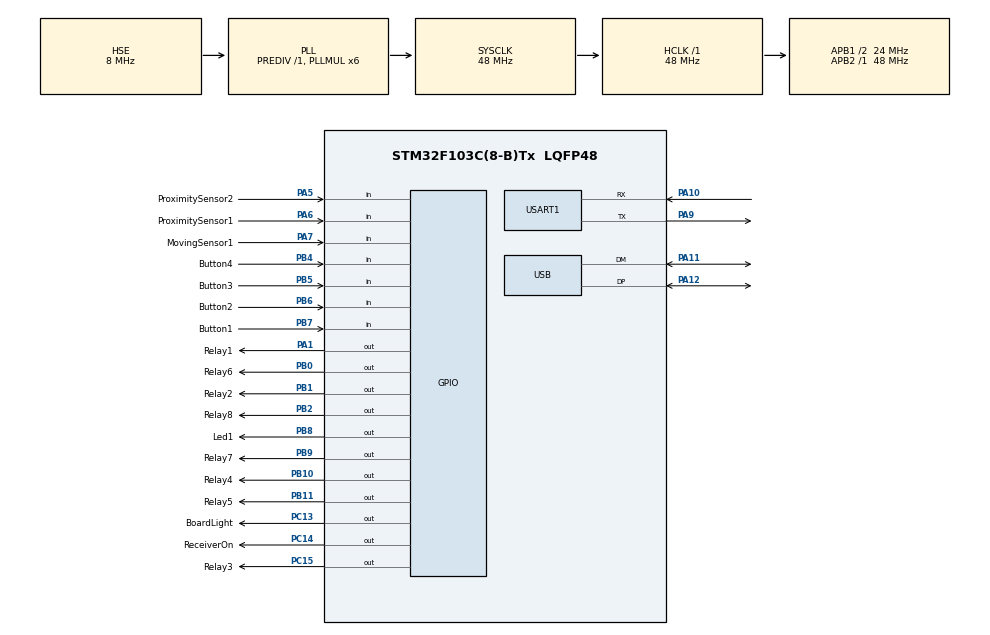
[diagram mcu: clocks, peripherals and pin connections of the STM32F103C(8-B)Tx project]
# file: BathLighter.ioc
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Dma.Request0=USART1_RX
Dma.Request1=USART1_TX
Dma.USART1_RX.0.Direction=DMA_PERIPH_TO_MEMORY
Dma.USART1_RX.0.Instance=DMA1_Channel5
Dma.USART1_RX.0.MemDataAlignment=DMA_MDATAALIGN_BYTE
Dma.USART1_RX.0.MemInc=DMA_MINC_ENABLE
Dma.USART1_RX.0.Mode=DMA_NORMAL
Dma.USART1_RX.0.PeriphDataAlignment=DMA_PDATAALIGN_BYTE
Dma.USART1_RX.0.PeriphInc=DMA_PINC_DISABLE
Dma.USART1_RX.0.Priority=DMA_PRIORITY_LOW
Dma.USART1_TX.1.Direction=DMA_MEMORY_TO_PERIPH
Dma.USART1_TX.1.Instance=DMA1_Channel4
Dma.USART1_TX.1.MemDataAlignment=DMA_MDATAALIGN_BYTE
Dma.USART1_TX.1.MemInc=DMA_MINC_ENABLE
Dma.USART1_TX.1.Mode=DMA_NORMAL
Dma.USART1_TX.1.PeriphDataAlignment=DMA_PDATAALIGN_BYTE
Dma.USART1_TX.1.PeriphInc=DMA_PINC_DISABLE
Dma.USART1_TX.1.Priority=DMA_PRIORITY_LOW
FREERTOS.Tasks01=NetTask,0,128,StartNetTask,Default,NULL,Dynamic,NULL,NULL;ReadSensors,0,128,StartReadSensorsTask,Default,NULL,Dynamic,NULL,NULL;Drive,0,128,StartDriveTask,Default,NULL,Dynamic,NULL,NULL
Mcu.Family=STM32F1
Mcu.Name=STM32F103C(8-B)Tx
Mcu.Package=LQFP48
Mcu.UserConstants=Timer2TicksMax,500
NVIC.DMA1_Channel4_IRQn=true\:5\:0\:false\:false\:true\:true\:false\:true
NVIC.DMA1_Channel5_IRQn=true\:5\:0\:false\:false\:true\:true\:false\:true
NVIC.PriorityGroup=NVIC_PRIORITYGROUP_4
NVIC.TIM1_UP_IRQn=true\:0\:0\:false\:false\:true\:false\:false\:true
NVIC.TIM2_IRQn=true\:5\:0\:false\:false\:true\:true\:true\:true
NVIC.TimeBase=TIM1_UP_IRQn
NVIC.TimeBaseIP=TIM1
NVIC.USART1_IRQn=true\:5\:0\:false\:false\:true\:true\:true\:true
NVIC.USB_HP_CAN1_TX_IRQn=true\:5\:0\:false\:false\:true\:true\:true\:true
NVIC.USB_LP_CAN1_RX0_IRQn=true\:5\:0\:false\:false\:true\:true\:false\:true
PA1.GPIO_Label=Relay1
PA1.Signal=GPIO_Output
PA10.Mode=Asynchronous
PA10.Signal=USART1_RX
PA11.Mode=Device
PA11.Signal=USB_DM
PA12.Mode=Device
PA12.Signal=USB_DP
PA13.Mode=Serial_Wire
PA13.Signal=SYS_JTMS-SWDIO
PA14.Mode=Serial_Wire
PA14.Signal=SYS_JTCK-SWCLK
PA5.GPIO_Label=ProximitySensor2
PA5.Signal=GPIO_Input
PA6.GPIO_Label=ProximitySensor1
PA6.Signal=GPIO_Input
PA7.GPIO_Label=MovingSensor1
PA7.Signal=GPIO_Input
PA9.Mode=Asynchronous
PA9.Signal=USART1_TX
PB0.GPIO_Label=Relay6
PB0.Signal=GPIO_Output
PB1.GPIO_Label=Relay2
PB1.Signal=GPIO_Output
PB10.GPIO_Label=Relay4
PB10.Signal=GPIO_Output
PB11.GPIO_Label=Relay5
PB11.Signal=GPIO_Output
PB2.GPIO_Label=Relay8
PB2.Signal=GPIO_Output
PB4.GPIO_Label=Button4
PB4.GPIO_PuPd=GPIO_NOPULL
PB4.Signal=GPIO_Input
PB5.GPIO_Label=Button3
PB5.GPIO_PuPd=GPIO_NOPULL
PB5.Signal=GPIO_Input
PB6.GPIO_Label=Button2
PB6.GPIO_PuPd=GPIO_NOPULL
PB6.Signal=GPIO_Input
PB7.GPIO_Label=Button1
PB7.GPIO_PuPd=GPIO_NOPULL
PB7.Signal=GPIO_Input
PB8.GPIO_Label=Led1
PB8.Signal=GPIO_Output
PB9.GPIO_Label=Relay7
PB9.Signal=GPIO_Output
PC13-TAMPER-RTC.GPIO_Label=BoardLight
PC13-TAMPER-RTC.Signal=GPIO_Output
PC14-OSC32_IN.GPIO_Label=ReceiverOn
PC14-OSC32_IN.Signal=GPIO_Output
PC15-OSC32_OUT.GPIO_Label=Relay3
PC15-OSC32_OUT.Signal=GPIO_Output
PD0-OSC_IN.Mode=HSE-External-Oscillator
PD0-OSC_IN.Signal=RCC_OSC_IN
PD1-OSC_OUT.Mode=HSE-External-Oscillator
PD1-OSC_OUT.Signal=RCC_OSC_OUT
ProjectManager.HeapSize=0x200
ProjectManager.StackSize=0x400
ProjectManager.TargetToolchain=EWARM V7
RCC.AHBFreq_Value=48000000
RCC.APB1CLKDivider=RCC_HCLK_DIV2
RCC.APB1Freq_Value=24000000
RCC.APB1TimFreq_Value=48000000
RCC.APB2Freq_Value=48000000
RCC.APB2TimFreq_Value=48000000
RCC.HCLKFreq_Value=48000000
RCC.PLLMUL=RCC_PLL_MUL6
RCC.SYSCLKFreq_VALUE=48000000
RCC.SYSCLKSource=RCC_SYSCLKSOURCE_PLLCLK
RCC.USBFreq_Value=48000000
TIM2.Period=9
TIM2.Prescaler=47999
USART1.VirtualMode=VM_ASYNC
USB_DEVICE.CLASS_NAME_FS=CUSTOM_HID
USB_DEVICE.USBD_CUSTOMHID_OUTREPORT_BUF_SIZE=16
USB_DEVICE.USBD_CUSTOM_HID_REPORT_DESC_SIZE=84
USB_DEVICE.VID=1164
USB_DEVICE.VirtualMode=CustomHid
USB_DEVICE.VirtualModeFS=Custom_Hid_FS
VP_FREERTOS_VS_CMSIS_V1.Mode=CMSIS_V1
VP_RTC_VS_RTC_Activate.Mode=RTC_Enabled
VP_RTC_VS_RTC_Calendar.Mode=RTC_Calendar
VP_SYS_VS_tim1.Mode=TIM1
VP_TIM2_VS_ClockSourceINT.Mode=Internal
VP_USB_DEVICE_VS_USB_DEVICE_CUSTOM_HID_FS.Mode=CUSTOM_HID_FS
board=NetMaster

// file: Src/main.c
/* USER CODE BEGIN Header */
/**
  ******************************************************************************
  * @file           : main.c
  * @brief          : Main program body
  ******************************************************************************
  * @attention
  *
  * <h2><center>&copy; Copyright (c) 2019 STMicroelectronics.
  * All rights reserved.</center></h2>
  *
  * This software component is licensed by ST under Ultimate Liberty license
  * SLA0044, the "License"; You may not use this file except in compliance with
  * the License. You may obtain a copy of the License at:
  *                             www.st.com/SLA0044
  *
  ******************************************************************************
  */
/* USER CODE END Header */

#include "main.h"
#include "cmsis_os.h"
#include "usb_device.h"

/* USER CODE BEGIN Includes */
#include "TasksForAll.h"
/* USER CODE END Includes */

RTC_HandleTypeDef hrtc;

TIM_HandleTypeDef htim2;

UART_HandleTypeDef huart1;
DMA_HandleTypeDef hdma_usart1_rx;
DMA_HandleTypeDef hdma_usart1_tx;

osThreadId NetTaskHandle;
osThreadId ReadSensorsHandle;
osThreadId DriveHandle;

void SystemClock_Config(void);
static void MX_GPIO_Init(void);
static void MX_DMA_Init(void);
static void MX_TIM2_Init(void);
static void MX_USART1_UART_Init(void);
static void MX_RTC_Init(void);
void StartNetTask(void const * argument);
void StartReadSensorsTask(void const * argument);
void StartDriveTask(void const * argument);

int main(void)
{

  /* MCU Configuration--------------------------------------------------------*/

  /* Reset of all peripherals, Initializes the Flash interface and the Systick. */
  HAL_Init();

  /* Configure the system clock */
  SystemClock_Config();

  /* Initialize all configured peripherals */
  MX_GPIO_Init();
  MX_DMA_Init();
  MX_TIM2_Init();
  MX_USART1_UART_Init();
  MX_RTC_Init();

  /* Create the thread(s) */
  /* definition and creation of NetTask */
  osThreadDef(NetTask, StartNetTask, osPriorityNormal, 0, 128);
  NetTaskHandle = osThreadCreate(osThread(NetTask), NULL);

  /* definition and creation of ReadSensors */
  osThreadDef(ReadSensors, StartReadSensorsTask, osPriorityNormal, 0, 128);
  ReadSensorsHandle = osThreadCreate(osThread(ReadSensors), NULL);

  /* definition and creation of Drive */
  osThreadDef(Drive, StartDriveTask, osPriorityNormal, 0, 128);
  DriveHandle = osThreadCreate(osThread(Drive), NULL);

  /* Start scheduler */
  osKernelStart();

  /* We should never get here as control is now taken by the scheduler */

  /* Infinite loop */
  while (1)
  {

  }
}

void SystemClock_Config(void)
{
  RCC_OscInitTypeDef RCC_OscInitStruct = {0};
  RCC_ClkInitTypeDef RCC_ClkInitStruct = {0};
  RCC_PeriphCLKInitTypeDef PeriphClkInit = {0};

  /** Initializes the CPU, AHB and APB busses clocks
  */
  RCC_OscInitStruct.OscillatorType = RCC_OSCILLATORTYPE_LSI|RCC_OSCILLATORTYPE_HSE;
  RCC_OscInitStruct.HSEState = RCC_HSE_ON;
  RCC_OscInitStruct.HSEPredivValue = RCC_HSE_PREDIV_DIV1;
  RCC_OscInitStruct.HSIState = RCC_HSI_ON;
  RCC_OscInitStruct.LSIState = RCC_LSI_ON;
  RCC_OscInitStruct.PLL.PLLState = RCC_PLL_ON;
  RCC_OscInitStruct.PLL.PLLSource = RCC_PLLSOURCE_HSE;
  RCC_OscInitStruct.PLL.PLLMUL = RCC_PLL_MUL6;
  if (HAL_RCC_OscConfig(&RCC_OscInitStruct) != HAL_OK)
  {
    Error_Handler();
  }
  /** Initializes the CPU, AHB and APB busses clocks
  */
  RCC_ClkInitStruct.ClockType = RCC_CLOCKTYPE_HCLK|RCC_CLOCKTYPE_SYSCLK
                              |RCC_CLOCKTYPE_PCLK1|RCC_CLOCKTYPE_PCLK2;
  RCC_ClkInitStruct.SYSCLKSource = RCC_SYSCLKSOURCE_PLLCLK;
  RCC_ClkInitStruct.AHBCLKDivider = RCC_SYSCLK_DIV1;
  RCC_ClkInitStruct.APB1CLKDivider = RCC_HCLK_DIV2;
  RCC_ClkInitStruct.APB2CLKDivider = RCC_HCLK_DIV1;

  if (HAL_RCC_ClockConfig(&RCC_ClkInitStruct, FLASH_LATENCY_1) != HAL_OK)
  {
    Error_Handler();
  }
  PeriphClkInit.PeriphClockSelection = RCC_PERIPHCLK_RTC|RCC_PERIPHCLK_USB;
  PeriphClkInit.RTCClockSelection = RCC_RTCCLKSOURCE_LSI;
  PeriphClkInit.UsbClockSelection = RCC_USBCLKSOURCE_PLL;
  if (HAL_RCCEx_PeriphCLKConfig(&PeriphClkInit) != HAL_OK)
  {
    Error_Handler();
  }
}

static void MX_RTC_Init(void)
{

  RTC_TimeTypeDef sTime = {0};
  RTC_DateTypeDef DateToUpdate = {0};

  /** Initialize RTC Only
  */
  hrtc.Instance = RTC;
  hrtc.Init.AsynchPrediv = RTC_AUTO_1_SECOND;
  hrtc.Init.OutPut = RTC_OUTPUTSOURCE_ALARM;
  if (HAL_RTC_Init(&hrtc) != HAL_OK)
  {
    Error_Handler();
  }

  /** Initialize RTC and set the Time and Date
  */
  sTime.Hours = 0x0;
  sTime.Minutes = 0x0;
  sTime.Seconds = 0x0;

  if (HAL_RTC_SetTime(&hrtc, &sTime, RTC_FORMAT_BCD) != HAL_OK)
  {
    Error_Handler();
  }
  DateToUpdate.WeekDay = RTC_WEEKDAY_MONDAY;
  DateToUpdate.Month = RTC_MONTH_JANUARY;
  DateToUpdate.Date = 0x1;
  DateToUpdate.Year = 0x0;

  if (HAL_RTC_SetDate(&hrtc, &DateToUpdate, RTC_FORMAT_BCD) != HAL_OK)
  {
    Error_Handler();
  }

}

static void MX_TIM2_Init(void)
{

  TIM_ClockConfigTypeDef sClockSourceConfig = {0};
  TIM_MasterConfigTypeDef sMasterConfig = {0};

  htim2.Instance = TIM2;
  htim2.Init.Prescaler = 47999;
  htim2.Init.CounterMode = TIM_COUNTERMODE_UP;
  htim2.Init.Period = 9;
  htim2.Init.ClockDivision = TIM_CLOCKDIVISION_DIV1;
  htim2.Init.AutoReloadPreload = TIM_AUTORELOAD_PRELOAD_DISABLE;
  if (HAL_TIM_Base_Init(&htim2) != HAL_OK)
  {
    Error_Handler();
  }
  sClockSourceConfig.ClockSource = TIM_CLOCKSOURCE_INTERNAL;
  if (HAL_TIM_ConfigClockSource(&htim2, &sClockSourceConfig) != HAL_OK)
  {
    Error_Handler();
  }
  sMasterConfig.MasterOutputTrigger = TIM_TRGO_RESET;
  sMasterConfig.MasterSlaveMode = TIM_MASTERSLAVEMODE_DISABLE;
  if (HAL_TIMEx_MasterConfigSynchronization(&htim2, &sMasterConfig) != HAL_OK)
  {
    Error_Handler();
  }

}

static void MX_USART1_UART_Init(void)
{

  huart1.Instance = USART1;
  huart1.Init.BaudRate = 115200;
  huart1.Init.WordLength = UART_WORDLENGTH_8B;
  huart1.Init.StopBits = UART_STOPBITS_1;
  huart1.Init.Parity = UART_PARITY_NONE;
  huart1.Init.Mode = UART_MODE_TX_RX;
  huart1.Init.HwFlowCtl = UART_HWCONTROL_NONE;
  huart1.Init.OverSampling = UART_OVERSAMPLING_16;
  if (HAL_UART_Init(&huart1) != HAL_OK)
  {
    Error_Handler();
  }

}

static void MX_DMA_Init(void)
{
  /* DMA controller clock enable */
  __HAL_RCC_DMA1_CLK_ENABLE();

  /* DMA interrupt init */
  /* DMA1_Channel4_IRQn interrupt configuration */
  HAL_NVIC_SetPriority(DMA1_Channel4_IRQn, 5, 0);
  HAL_NVIC_EnableIRQ(DMA1_Channel4_IRQn);
  /* DMA1_Channel5_IRQn interrupt configuration */
  HAL_NVIC_SetPriority(DMA1_Channel5_IRQn, 5, 0);
  HAL_NVIC_EnableIRQ(DMA1_Channel5_IRQn);

}

static void MX_GPIO_Init(void)
{
  GPIO_InitTypeDef GPIO_InitStruct = {0};

  /* GPIO Ports Clock Enable */
  __HAL_RCC_GPIOC_CLK_ENABLE();
  __HAL_RCC_GPIOD_CLK_ENABLE();
  __HAL_RCC_GPIOA_CLK_ENABLE();
  __HAL_RCC_GPIOB_CLK_ENABLE();

  /*Configure GPIO pin Output Level */
  HAL_GPIO_WritePin(GPIOC, BoardLight_Pin|ReceiverOn_Pin|Relay3_Pin, GPIO_PIN_RESET);

  /*Configure GPIO pin Output Level */
  HAL_GPIO_WritePin(Relay1_GPIO_Port, Relay1_Pin, GPIO_PIN_RESET);

  /*Configure GPIO pin Output Level */
  HAL_GPIO_WritePin(GPIOB, Relay6_Pin|Relay2_Pin|Relay8_Pin|Relay4_Pin
                          |Relay5_Pin|Led1_Pin|Relay7_Pin, GPIO_PIN_RESET);

  /*Configure GPIO pins : BoardLight_Pin ReceiverOn_Pin Relay3_Pin */
  GPIO_InitStruct.Pin = BoardLight_Pin|ReceiverOn_Pin|Relay3_Pin;
  GPIO_InitStruct.Mode = GPIO_MODE_OUTPUT_PP;
  GPIO_InitStruct.Pull = GPIO_NOPULL;
  GPIO_InitStruct.Speed = GPIO_SPEED_FREQ_LOW;
  HAL_GPIO_Init(GPIOC, &GPIO_InitStruct);

  /*Configure GPIO pin : Relay1_Pin */
  GPIO_InitStruct.Pin = Relay1_Pin;
  GPIO_InitStruct.Mode = GPIO_MODE_OUTPUT_PP;
  GPIO_InitStruct.Pull = GPIO_NOPULL;
  GPIO_InitStruct.Speed = GPIO_SPEED_FREQ_LOW;
  HAL_GPIO_Init(Relay1_GPIO_Port, &GPIO_InitStruct);

  /*Configure GPIO pins : ProximitySensor2_Pin ProximitySensor1_Pin MovingSensor1_Pin */
  GPIO_InitStruct.Pin = ProximitySensor2_Pin|ProximitySensor1_Pin|MovingSensor1_Pin;
  GPIO_InitStruct.Mode = GPIO_MODE_INPUT;
  GPIO_InitStruct.Pull = GPIO_NOPULL;
  HAL_GPIO_Init(GPIOA, &GPIO_InitStruct);

  /*Configure GPIO pins : Relay6_Pin Relay2_Pin Relay8_Pin Relay4_Pin
                           Relay5_Pin Led1_Pin Relay7_Pin */
  GPIO_InitStruct.Pin = Relay6_Pin|Relay2_Pin|Relay8_Pin|Relay4_Pin
                          |Relay5_Pin|Led1_Pin|Relay7_Pin;
  GPIO_InitStruct.Mode = GPIO_MODE_OUTPUT_PP;
  GPIO_InitStruct.Pull = GPIO_NOPULL;
  GPIO_InitStruct.Speed = GPIO_SPEED_FREQ_LOW;
  HAL_GPIO_Init(GPIOB, &GPIO_InitStruct);

  /*Configure GPIO pins : Button4_Pin Button3_Pin Button2_Pin Button1_Pin */
  GPIO_InitStruct.Pin = Button4_Pin|Button3_Pin|Button2_Pin|Button1_Pin;
  GPIO_InitStruct.Mode = GPIO_MODE_INPUT;
  GPIO_InitStruct.Pull = GPIO_NOPULL;
  HAL_GPIO_Init(GPIOB, &GPIO_InitStruct);

}

void StartNetTask(void const * argument)
{
  /* init code for USB_DEVICE */
  MX_USB_DEVICE_Init();

  /* USER CODE BEGIN 5 */

  /* Infinite loop */
  for(;;)
  {
  Communication();
  osDelay(1);
  }
  /* USER CODE END 5 */
}

void StartReadSensorsTask(void const * argument)
{
  /* USER CODE BEGIN StartReadSensorsTask */
  /* Infinite loop */
  for(;;)
  {
  ReadSensors();
  osDelay(1);
  }
  /* USER CODE END StartReadSensorsTask */
}

void StartDriveTask(void const * argument)
{
  /* USER CODE BEGIN StartDriveTask */
  Initialization ();
  /* Infinite loop */
  for(;;)
  {
    HAL_RTC_Init(&hrtc);
    Drive();
    osDelay(1);
  }
  /* USER CODE END StartDriveTask */
}

void HAL_TIM_PeriodElapsedCallback(TIM_HandleTypeDef *htim)
{
  if (htim->Instance == TIM1) {
    HAL_IncTick();
  }
}

void Error_Handler(void)
{
}

/************************ (C) COPYRIGHT STMicroelectronics *****END OF FILE****/
